VERSION ""

NS_ :

BS_:

BU_: RVCController

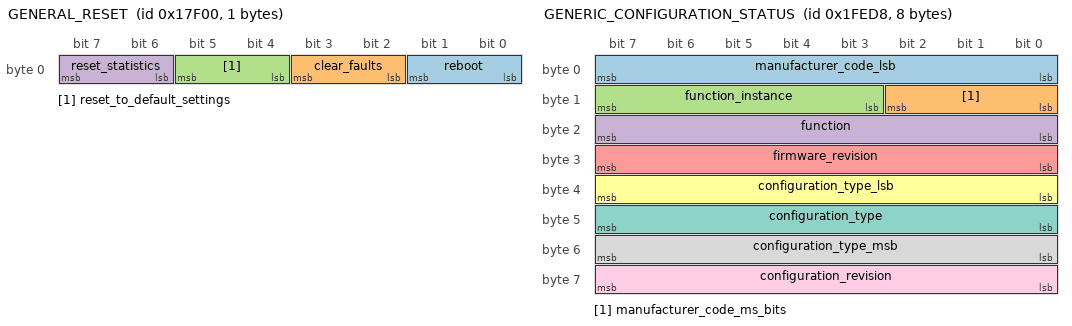
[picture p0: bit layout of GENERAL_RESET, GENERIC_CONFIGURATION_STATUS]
BO_ 98048 GENERAL_RESET: 1 RVCController
 SG_ reboot : 0|2@1+ (1,0) [0|0] "" RVCController
 SG_ clear_faults : 2|2@1+ (1,0) [0|0] "" RVCController
 SG_ reset_to_default_settings : 4|2@1+ (1,0) [0|0] "" RVCController
 SG_ reset_statistics : 6|2@1+ (1,0) [0|0] "" RVCController
VAL_ 98048 reboot 0 "no action" 1 "Reboot" ;
VAL_ 98048 clear_faults 0 "no action" 1 "clear faults" ;
VAL_ 98048 reset_to_default_settings 0 "no action" 1 "reset to default settings" ;
VAL_ 98048 reset_statistics 0 "no action" 1 "reset statistics" ;

BO_ 97792 TERMINAL: 8 RVCController
 SG_ unknown : 0|8@1+ (1,0) [0|0] "" RVCController
 // NOTE: YAML defines this as 8 bytes ASCII. DBC representation is ambiguous. Leaving as is.

BO_ 130776 GENERIC_CONFIGURATION_STATUS: 8 RVCController
 SG_ manufacturer_code_lsb : 0|8@1+ (1,0) [0|0] "" RVCController
 SG_ manufacturer_code_ms_bits : 8|3@1+ (1,0) [0|0] "" RVCController
 SG_ function_instance : 11|5@1+ (1,0) [0|0] "" RVCController
 SG_ function : 16|8@1+ (1,0) [0|0] "" RVCController
 SG_ firmware_revision : 24|8@1+ (1,0) [0|0] "" RVCController
 SG_ configuration_type_lsb : 32|8@1+ (1,0) [0|0] "" RVCController
 SG_ configuration_type : 40|8@1+ (1,0) [0|0] "" RVCController
 SG_ configuration_type_msb : 48|8@1+ (1,0) [0|0] "" RVCController
 SG_ configuration_revision : 56|8@1+ (1,0) [0|0] "" RVCController

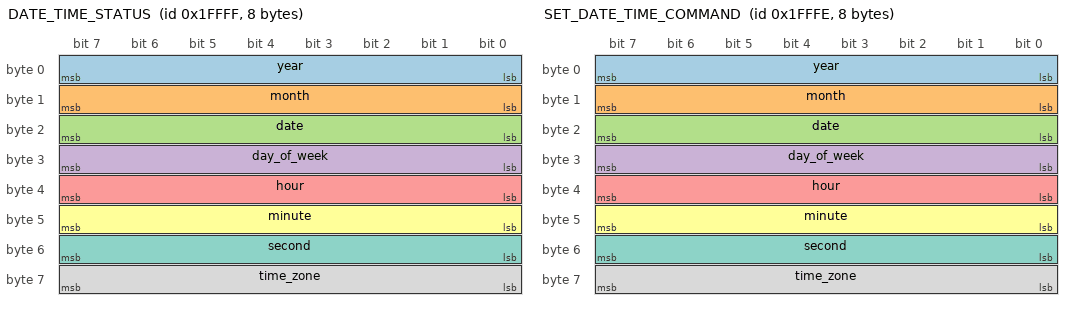
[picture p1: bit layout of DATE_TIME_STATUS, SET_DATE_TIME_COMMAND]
BO_ 131071 DATE_TIME_STATUS: 8 RVCController
 SG_ year : 0|8@1+ (1,0) [0|0] "year" RVCController
 SG_ month : 8|8@1+ (1,0) [0|0] "" RVCController
 SG_ date : 16|8@1+ (1,0) [0|0] "" RVCController
 SG_ day_of_week : 24|8@1+ (1,0) [0|0] "" RVCController
 SG_ hour : 32|8@1+ (1,0) [0|0] "" RVCController
 SG_ minute : 40|8@1+ (1,0) [0|0] "" RVCController
 SG_ second : 48|8@1+ (1,0) [0|0] "" RVCController
 SG_ time_zone : 56|8@1+ (1,0) [0|0] "" RVCController
VAL_ 131071 day_of_week 1 "Sunday" 2 "Monday" 3 "Tuesday" 4 "Wednesday" 5 "Thursday" 6 "Friday" 7 "Saturday" ;
VAL_ 131071 time_zone 0 "Greenwich Mean Time" 4 "Eastern Daylight Time" 5 "Eastern Standard Time" 7 "Pacific Daylight Time" 8 "Pacific Standard Time" 22 "Central European Summer Time" ;

// Add missing alias from YAML: 1FFFE SET_DATE_TIME_COMMAND (alias of 1FFFF)
BO_ 131070 SET_DATE_TIME_COMMAND: 8 RVCController
 SG_ year : 0|8@1+ (1,0) [0|0] "year" RVCController
 SG_ month : 8|8@1+ (1,0) [0|0] "" RVCController
 SG_ date : 16|8@1+ (1,0) [0|0] "" RVCController
 SG_ day_of_week : 24|8@1+ (1,0) [0|0] "" RVCController
 SG_ hour : 32|8@1+ (1,0) [0|0] "" RVCController
 SG_ minute : 40|8@1+ (1,0) [0|0] "" RVCController
 SG_ second : 48|8@1+ (1,0) [0|0] "" RVCController
 SG_ time_zone : 56|8@1+ (1,0) [0|0] "" RVCController
VAL_ 131070 day_of_week 1 "Sunday" 2 "Monday" 3 "Tuesday" 4 "Wednesday" 5 "Thursday" 6 "Friday" 7 "Saturday" ;
VAL_ 131070 time_zone 0 "Greenwich Mean Time" 4 "Eastern Daylight Time" 5 "Eastern Standard Time" 7 "Pacific Daylight Time" 8 "Pacific Standard Time" 22 "Central European Summer Time" ;

BO_ 131069 DC_SOURCE_STATUS_1: 8 RVCController
 SG_ instance : 0|8@1+ (1,0) [0|0] "" RVCController
 SG_ device_priority : 8|8@1+ (1,0) [0|0] "" RVCController
 SG_ dc_voltage : 16|16@1+ (0.001,0) [0|0] "V" RVCController // Assuming scaling based on typical usage
 SG_ dc_current : 32|32@1+ (0.001,0) [0|0] "A" RVCController // Assuming scaling based on typical usage
VAL_ 131069 instance 0 "invalid" 1 "main house battery bank" 2 "chassis start battery" 3 "secondary house battery bank" ;
VAL_ 131069 device_priority 120 "battery soc device" 100 "inverter charger" 80 "charger" 60 "inverter" 40 "voltmeter ammeter" 20 "voltmeter" ; // Corrected 100

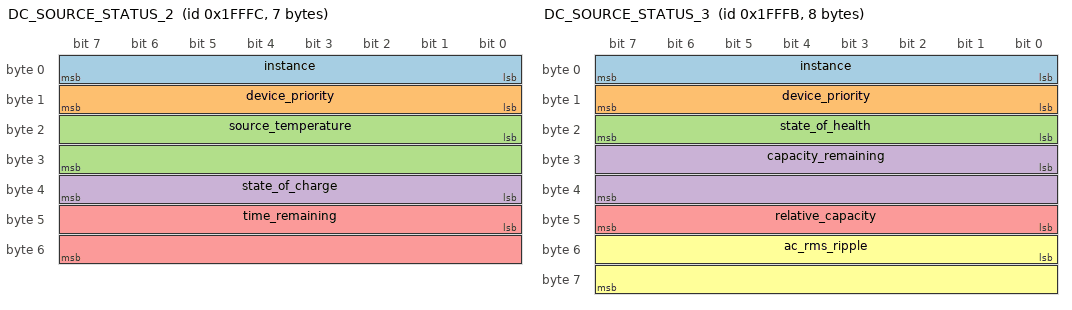
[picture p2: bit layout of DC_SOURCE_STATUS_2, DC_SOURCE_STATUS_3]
BO_ 131068 DC_SOURCE_STATUS_2: 7 RVCController
 SG_ instance : 0|8@1+ (1,0) [0|0] "" RVCController
 SG_ device_priority : 8|8@1+ (1,0) [0|0] "" RVCController
 SG_ source_temperature : 16|16@1+ (0.1,-40) [0|0] "Deg C" RVCController // Assuming scaling based on typical usage
 SG_ state_of_charge : 32|8@1+ (0.5,0) [0|0] "pct" RVCController // Assuming scaling based on typical usage
 SG_ time_remaining : 40|16@1+ (1,0) [0|0] "min" RVCController
VAL_ 131068 instance 0 "invalid" 1 "main house battery bank" 2 "chassis start battery" 3 "secondary house battery bank" ;
VAL_ 131068 device_priority 120 "battery soc device" 100 "inverter Charger" 80 "charger" 60 "inverter" 40 "voltmeter ammeter" 20 "voltmeter" ; // Corrected 100

BO_ 131067 DC_SOURCE_STATUS_3: 8 RVCController
 SG_ instance : 0|8@1+ (1,0) [0|0] "" RVCController
 SG_ device_priority : 8|8@1+ (1,0) [0|0] "" RVCController
 SG_ state_of_health : 16|8@1+ (0.5,0) [0|0] "pct" RVCController // Assuming scaling
 SG_ capacity_remaining : 24|16@1+ (0.1,0) [0|0] "Ah" RVCController // Assuming scaling
 SG_ relative_capacity : 40|8@1+ (0.5,0) [0|0] "pct" RVCController // Assuming scaling
 SG_ ac_rms_ripple : 48|16@1+ (1,0) [0|0] "mV" RVCController
VAL_ 131067 instance 0 "invalid" 1 "main house battery bank" 2 "chassis start battery" 3 "secondary house battery bank" ;
VAL_ 131067 device_priority 120 "battery soc device" 100 "inverter charger" 80 "charger" 60 "inverter" 40 "voltmeter ammeter" 20 "voltmeter" ; // Corrected 100

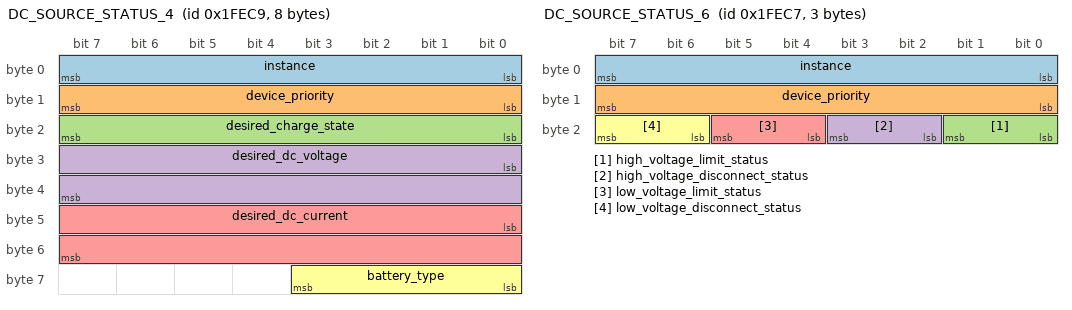
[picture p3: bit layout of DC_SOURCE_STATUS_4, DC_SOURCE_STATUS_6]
BO_ 130761 DC_SOURCE_STATUS_4: 8 RVCController
 SG_ instance : 0|8@1+ (1,0) [0|0] "" RVCController
 SG_ device_priority : 8|8@1+ (1,0) [0|0] "" RVCController
 SG_ desired_charge_state : 16|8@1+ (1,0) [0|0] "" RVCController
 SG_ desired_dc_voltage : 24|16@1+ (0.001,0) [0|0] "V" RVCController // Assuming scaling
 SG_ desired_dc_current : 40|16@1+ (0.1,0) [0|0] "A" RVCController // Assuming scaling
 SG_ battery_type : 56|4@1+ (1,0) [0|0] "" RVCController
VAL_ 130761 instance 0 "invalid" 1 "main house battery bank" 2 "chassis start battery" 3 "secondary house battery bank" ;
VAL_ 130761 device_priority 120 "battery soc device" 100 "inverter charger" 80 "charger" 60 "inverter" 40 "voltmeter ammeter" 20 "voltmeter" ; // Corrected 100
VAL_ 130761 desired_charge_state 0 "undefined" 1 "do not charge" 2 "bulk" 3 "absorbtion" 4 "overcharge" 5 "equalize" 6 "float" 7 "constant voltage current" ;
VAL_ 130761 battery_type 0 "flooded" 1 "gel" 2 "agm" 3 "lithium iron phosphate" ;

BO_ 130760 DC_SOURCE_STATUS_5: 8 RVCController
 SG_ instance : 0|8@1+ (1,0) [0|0] "" RVCController
 SG_ device_priority : 8|8@1+ (1,0) [0|0] "" RVCController
 SG_ hp_dc_voltage : 16|32@1+ (0.000001,0) [0|0] "V" RVCController // Assuming scaling
 SG_ dc_voltage_rate_of_change : 48|16@1+ (0.001,0) [0|0] "mV/s" RVCController // Assuming scaling
VAL_ 130760 instance 0 "invalid" 1 "main house battery bank" 2 "chassis start battery" 3 "secondary house battery bank" ;
VAL_ 130760 device_priority 120 "battery soc device" 100 "inverter charger" 80 "charger" 60 "inverter" 40 "voltmeter ammeter" 20 "voltmeter" ; // Corrected 100

BO_ 130759 DC_SOURCE_STATUS_6: 3 RVCController
 SG_ instance : 0|8@1+ (1,0) [0|0] "" RVCController
 SG_ device_priority : 8|8@1+ (1,0) [0|0] "" RVCController
 SG_ high_voltage_limit_status : 16|2@1+ (1,0) [0|0] "" RVCController
 SG_ high_voltage_disconnect_status : 18|2@1+ (1,0) [0|0] "" RVCController
 SG_ low_voltage_limit_status : 20|2@1+ (1,0) [0|0] "" RVCController
 SG_ low_voltage_disconnect_status : 22|2@1+ (1,0) [0|0] "" RVCController
VAL_ 130759 instance 0 "invalid" 1 "main house battery bank" 2 "chassis start battery" 3 "secondary house battery bank" ;
VAL_ 130759 device_priority 120 "battery soc device" 100 "inverter charger" 80 "charger" 60 "inverter" 40 "voltmeter ammeter" 20 "voltmeter" ; // Corrected 100
VAL_ 130759 high_voltage_limit_status 0 "not reached" 1 "limit reached" ;
VAL_ 130759 high_voltage_disconnect_status 0 "connected" 1 "charge bus disconnected" ;
VAL_ 130759 low_voltage_limit_status 0 "not reached" 1 "limit reached" ;
VAL_ 130759 low_voltage_disconnect_status 0 "connected" 1 "charge bus disconnected" ;

// Add missing alias from YAML: 10FFD DC_SOURCE_STATUS_SPYDER (alias of 1FFFD)
BO_ 69629 DC_SOURCE_STATUS_SPYDER: 8 RVCController
 SG_ instance : 0|8@1+ (1,0) [0|0] "" RVCController
 SG_ device_priority : 8|8@1+ (1,0) [0|0] "" RVCController
 SG_ dc_voltage : 16|16@1+ (0.001,0) [0|0] "V" RVCController // Assuming scaling
 SG_ dc_current : 32|32@1+ (0.001,0) [0|0] "A" RVCController // Assuming scaling
VAL_ 69629 instance 0 "invalid" 1 "main house battery bank" 2 "chassis start battery" 3 "secondary house battery bank" ;
VAL_ 69629 device_priority 120 "battery soc device" 100 "inverter charger" 80 "charger" 60 "inverter" 40 "voltmeter ammeter" 20 "voltmeter" ; // Corrected 100

BO_ 131066 COMMUNICATION_STATUS_1: 8 RVCController
 SG_ timer_count : 0|32@1+ (1,0) [0|0] "ms" RVCController
 SG_ receive_error_count : 32|16@1+ (1,0) [0|0] "" RVCController
 SG_ transmit_error_count : 48|16@1+ (1,0) [0|0] "" RVCController

BO_ 131065 COMMUNICATION_STATUS_2: 8 RVCController
 SG_ transmitted_frames_count : 0|32@1+ (1,0) [0|0] "" RVCController
 SG_ received_frames_count : 32|32@1+ (1,0) [0|0] "" RVCController

BO_ 131064 COMMUNICATION_STATUS_3: 6 RVCController
 SG_ bus_off_error_count : 0|16@1+ (1,0) [0|0] "" RVCController
 SG_ receive_frames_dropped_count : 16|16@1+ (1,0) [0|0] "" RVCController
 SG_ transmit_frames_dropped_count : 32|16@1+ (1,0) [0|0] "" RVCController

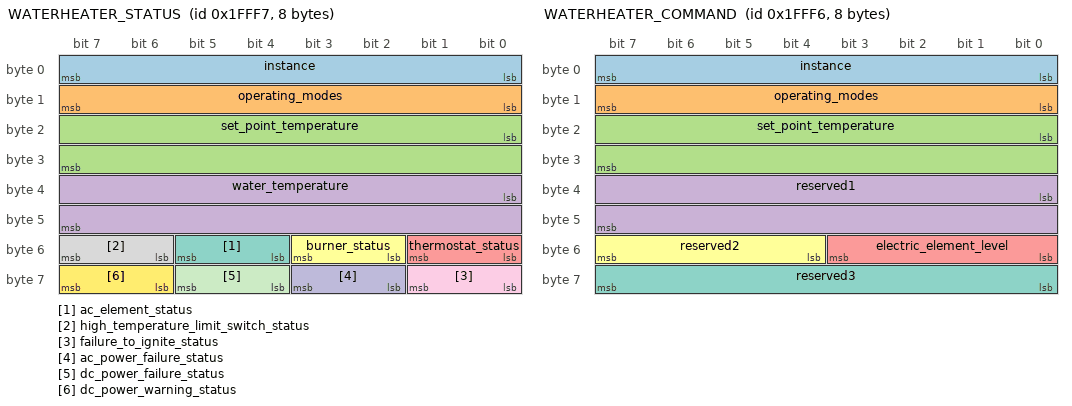
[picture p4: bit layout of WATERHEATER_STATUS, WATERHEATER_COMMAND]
BO_ 131063 WATERHEATER_STATUS: 8 RVCController
 SG_ instance : 0|8@1+ (1,0) [0|0] "" RVCController
 SG_ operating_modes : 8|8@1+ (1,0) [0|0] "" RVCController
 SG_ set_point_temperature : 16|16@1+ (0.1,0) [0|0] "Deg C" RVCController // Assuming scaling
 SG_ water_temperature : 32|16@1+ (0.1,0) [0|0] "Deg C" RVCController // Assuming scaling
 SG_ thermostat_status : 48|2@1+ (1,0) [0|0] "" RVCController
 SG_ burner_status : 50|2@1+ (1,0) [0|0] "" RVCController
 SG_ ac_element_status : 52|2@1+ (1,0) [0|0] "" RVCController
 SG_ high_temperature_limit_switch_status : 54|2@1+ (1,0) [0|0] "" RVCController
 SG_ failure_to_ignite_status : 56|2@1+ (1,0) [0|0] "" RVCController
 SG_ ac_power_failure_status : 58|2@1+ (1,0) [0|0] "" RVCController
 SG_ dc_power_failure_status : 60|2@1+ (1,0) [0|0] "" RVCController
 SG_ dc_power_warning_status : 62|2@1+ (1,0) [0|0] "" RVCController
VAL_ 131063 operating_modes 0 "off" 1 "combustion" 2 "electric" 3 "gas/electric (both)" 4 "automatic (electric if available, otherwise combustion)" 5 "test combustion (forced on)" 6 "test electric (forced on)" ; // Corrected 0 value
VAL_ 131063 thermostat_status 0 "set point met" 1 "set point not met (heat is being applied)" ;
VAL_ 131063 burner_status 0 "off" 1 "burner is lit" ; // Corrected 0 value
VAL_ 131063 ac_element_status 0 "ac element is inactive" 1 "ac element is active" ;
VAL_ 131063 high_temperature_limit_switch_status 0 "limit switch not tripped" 1 "limit switch tripped" ;
VAL_ 131063 failure_to_ignite_status 0 "no failure" 1 "device has failed to ignite" ;
VAL_ 131063 ac_power_failure_status 0 "ac power present" 1 "ac power not present" ;
VAL_ 131063 dc_power_failure_status 0 "dc power present" 1 "dc power not present" ;
VAL_ 131063 dc_power_warning_status 0 "dc power sufficient" 1 "dc power warning" ;

BO_ 131062 WATERHEATER_COMMAND: 8 RVCController
 SG_ instance : 0|8@1+ (1,0) [0|0] "" RVCController
 SG_ operating_modes : 8|8@1+ (1,0) [0|0] "" RVCController
 SG_ set_point_temperature : 16|16@1+ (0.1,0) [0|0] "" RVCController // Assuming scaling
 SG_ reserved1 : 32|16@1+ (1,0) [0|0] "" RVCController // Renamed reserved
 SG_ electric_element_level : 48|4@1+ (1,0) [0|0] "" RVCController
 SG_ reserved2 : 52|4@1+ (1,0) [0|0] "" RVCController // Renamed reserved
 SG_ reserved3 : 56|8@1+ (1,0) [0|0] "" RVCController // Renamed reserved
VAL_ 131062 operating_modes 0 "off" 1 "combustion" 2 "electric" 3 "gas/electric (both)" 4 "automatic (electric if available, combustion otherwise)" 5 "test combustion (forced on)" 6 "test electric (forced on)" ; // Corrected 0 value

BO_ 130713 WATERHEATER_STATUS_2: 8 RVCController
 SG_ instance : 0|8@1+ (1,0) [0|0] "" RVCController
 SG_ electric_element_level : 8|4@1+ (1,0) [0|0] "" RVCController
 SG_ max_electric_element_level : 12|4@1+ (1,0) [0|0] "" RVCController
 SG_ engine_preheat : 16|4@1+ (1,0) [0|0] "" RVCController
 SG_ coolant_level_warning : 20|2@1+ (1,0) [0|0] "" RVCController
 SG_ hot_water_priority : 22|2@1+ (1,0) [0|0] "" RVCController
 SG_ output_status_burner : 24|2@1+ (1,0) [0|0] "" RVCController // Normalized name
 SG_ output_status_burner_indicator : 26|2@1+ (1,0) [0|0] "" RVCController // Normalized name
 SG_ output_status_electric_low : 28|2@1+ (1,0) [0|0] "" RVCController // Normalized name
 SG_ output_status_electric_high : 30|2@1+ (1,0) [0|0] "" RVCController // Normalized name
 SG_ burner_overcurrent_status : 32|2@1+ (1,0) [0|0] "" RVCController
 SG_ burner_undercurrent_status : 34|2@1+ (1,0) [0|0] "" RVCController
 SG_ burner_temperature_status : 36|2@1+ (1,0) [0|0] "" RVCController
 SG_ burner_input_status : 38|2@1+ (1,0) [0|0] "" RVCController
 SG_ burner_indicator_overcurrent_status : 40|2@1+ (1,0) [0|0] "" RVCController
 SG_ burner_indicator_undercurrent_status : 42|2@1+ (1,0) [0|0] "" RVCController
 SG_ burner_indicator_temperature_status : 44|2@1+ (1,0) [0|0] "" RVCController
 SG_ reserved : 46|2@1+ (1,0) [0|0] "" RVCController
 SG_ electric_low_overcurrent_status : 48|2@1+ (1,0) [0|0] "" RVCController
 SG_ electric_low_undercurrent_status : 50|2@1+ (1,0) [0|0] "" RVCController
 SG_ electric_low_temperature_status : 52|2@1+ (1,0) [0|0] "" RVCController
 SG_ electric_low_input_status : 54|2@1+ (1,0) [0|0] "" RVCController
 SG_ electric_high_element_overcurrent_status : 56|2@1+ (1,0) [0|0] "" RVCController
 SG_ electric_high_element_undercurrent_status : 58|2@1+ (1,0) [0|0] "" RVCController
 SG_ electric_high_element_temperature_status : 60|2@1+ (1,0) [0|0] "" RVCController
 SG_ electric_high_element_input_status : 62|2@1+ (1,0) [0|0] "" RVCController
VAL_ 130713 engine_preheat 0 "off" 1 "on" 5 "test (forced on)" ; // Corrected values
VAL_ 130713 coolant_level_warning 0 "coolant level sufficent" 1 "coolant level low (shutoff)" ;
VAL_ 130713 hot_water_priority 0 "domestic water priority" 1 "heating priority" ;
VAL_ 130713 output_status_burner 0 "off" 1 "on" ; // Normalized name and values
VAL_ 130713 output_status_burner_indicator 0 "off" 1 "on" ; // Normalized name and values
VAL_ 130713 output_status_electric_low 0 "off" 1 "on" ; // Normalized name and values
VAL_ 130713 output_status_electric_high 0 "off" 1 "on" ; // Normalized name and values
VAL_ 130713 burner_overcurrent_status 0 "no overcurrent detected" 1 "overcurrent detected" ;
VAL_ 130713 burner_undercurrent_status 0 "no undercurrent detected" 1 "undercurrent detected" ;
VAL_ 130713 burner_temperature_status 0 "temperature normal" 1 "temperature warning" ;
VAL_ 130713 burner_input_status 0 "off (inactive)" 1 "on (active)" ;
VAL_ 130713 burner_indicator_overcurrent_status 0 "no overcurrent detected" 1 "overcurrent detected" ;
VAL_ 130713 burner_indicator_undercurrent_status 0 "no undercurrent detected" 1 "undercurrent detected" ;
VAL_ 130713 burner_indicator_temperature_status 0 "temperature normal" 1 "temperature warning" ;
VAL_ 130713 electric_low_overcurrent_status 0 "no overcurrent detected" 1 "overcurrent detected" ;
VAL_ 130713 electric_low_undercurrent_status 0 "no undercurrent detected" 1 "undercurrent detected" ;
VAL_ 130713 electric_low_temperature_status 0 "temperature normal" 1 "temperature warning" ;
VAL_ 130713 electric_low_input_status 0 "off (inactive)" 1 "on (active)" ;
VAL_ 130713 electric_high_element_overcurrent_status 0 "no overcurrent detected" 1 "overcurrent detected" ;
VAL_ 130713 electric_high_element_undercurrent_status 0 "no undercurrent detected" 1 "undercurrent detected" ;
VAL_ 130713 electric_high_element_temperature_status 0 "temperature normal" 1 "temperature warning" ;
VAL_ 130713 electric_high_element_input_status 0 "off (inactive)" 1 "on (active)" ;

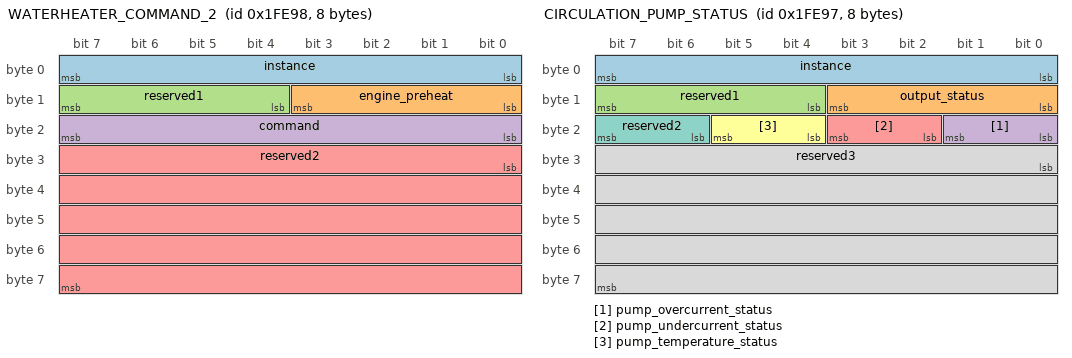
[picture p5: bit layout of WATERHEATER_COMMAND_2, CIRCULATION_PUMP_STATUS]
BO_ 130712 WATERHEATER_COMMAND_2: 8 RVCController
 SG_ instance : 0|8@1+ (1,0) [0|0] "" RVCController
 SG_ engine_preheat : 8|4@1+ (1,0) [0|0] "" RVCController
 SG_ reserved1 : 12|4@1+ (1,0) [0|0] "" RVCController // Renamed reserved
 SG_ command : 16|8@1+ (1,0) [0|0] "" RVCController
 SG_ reserved2 : 24|40@1+ (1,0) [0|0] "" RVCController // Renamed reserved, corrected length
VAL_ 130712 engine_preheat 0 "off" 1 "on" 5 "test (forced on)" ; // Corrected values
VAL_ 130712 command 0 "electric low - enable" 1 "electric low - disable" 2 "electric low - toggle" 3 "electric high - enable" 4 "electric High - disable" 5 "electric High - toggle" 6 "burner - enable" 7 "burner - disable" 8 "burner - toggle" 9 "electric - cycle (low to high to off)" 10 "electric - cycle (high to low to off)" 11 "electric low test - toggle" 12 "electric high test - toggle" 13 "burner test - toggle" ; // Corrected values 10-13

// Add missing message from YAML: 1FE97 CIRCULATION_PUMP_STATUS
BO_ 130711 CIRCULATION_PUMP_STATUS: 8 RVCController // Assuming length 8 based on reserved bits
 SG_ instance : 0|8@1+ (1,0) [0|0] "" RVCController
 SG_ output_status : 8|4@1+ (1,0) [0|0] "" RVCController
 SG_ reserved1 : 12|4@1+ (1,0) [0|0] "" RVCController
 SG_ pump_overcurrent_status : 16|2@1+ (1,0) [0|0] "" RVCController
 SG_ pump_undercurrent_status : 18|2@1+ (1,0) [0|0] "" RVCController // Corrected length based on values
 SG_ pump_temperature_status : 20|2@1+ (1,0) [0|0] "" RVCController // Corrected length based on values
 SG_ reserved2 : 22|2@1+ (1,0) [0|0] "" RVCController
 SG_ reserved3 : 24|40@1+ (1,0) [0|0] "" RVCController
VAL_ 130711 output_status 0 "off" 1 "on" 5 "test (forced on)" ;
VAL_ 130711 pump_overcurrent_status 0 "no overcurrent detected" 1 "overcurrent detected" ;
VAL_ 130711 pump_undercurrent_status 0 "no undercurrent detected" 1 "undercurrent detected" ;
VAL_ 130711 pump_temperature_status 0 "temperature normal" 1 "temperature warning" ;

// Add missing message from YAML: 1FE96 CIRCULATION_PUMP_COMMAND
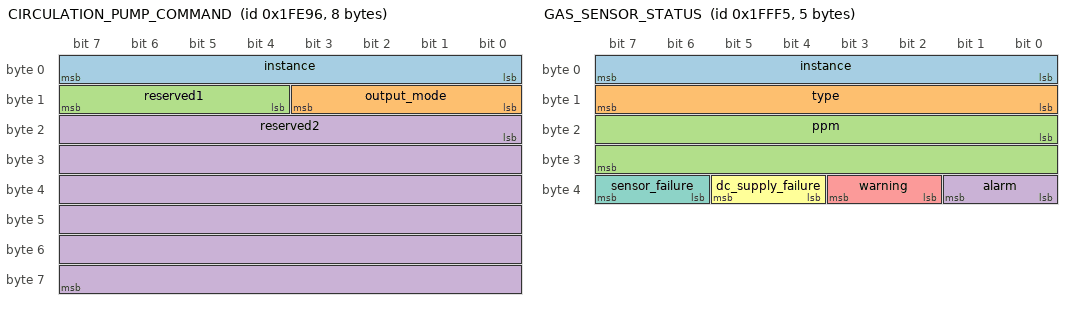
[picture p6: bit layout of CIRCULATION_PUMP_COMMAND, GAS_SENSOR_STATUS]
BO_ 130710 CIRCULATION_PUMP_COMMAND: 8 RVCController // Assuming length 8 based on reserved bits
 SG_ instance : 0|8@1+ (1,0) [0|0] "" RVCController
 SG_ output_mode : 8|4@1+ (1,0) [0|0] "" RVCController
 SG_ reserved1 : 12|4@1+ (1,0) [0|0] "" RVCController
 SG_ reserved2 : 16|48@1+ (1,0) [0|0] "" RVCController
VAL_ 130710 output_mode 0 "off" 5 "test (forced on)" ;

BO_ 131061 GAS_SENSOR_STATUS: 5 RVCController
 SG_ instance : 0|8@1+ (1,0) [0|0] "" RVCController
 SG_ type : 8|8@1+ (1,0) [0|0] "" RVCController
 SG_ ppm : 16|16@1+ (1,0) [0|0] "ppm" RVCController
 SG_ alarm : 32|2@1+ (1,0) [0|0] "" RVCController // Removed unit="bit"
 SG_ warning : 34|2@1+ (1,0) [0|0] "" RVCController // Removed unit="bit"
 SG_ dc_supply_failure : 36|2@1+ (1,0) [0|0] "" RVCController // Removed unit="bit"
 SG_ sensor_failure : 38|2@1+ (1,0) [0|0] "" RVCController // Removed unit="bit"
VAL_ 131061 type 1 "co" 2 "lp gas" 3 "smoke" ;
VAL_ 131061 alarm 0 "no alarm" 1 "alarm" ;
VAL_ 131061 warning 0 "no warning" 1 "warning" ;
VAL_ 131061 dc_supply_failure 0 "no failure" 1 "failure" ;
VAL_ 131061 sensor_failure 0 "no failure" 1 "failure" ;

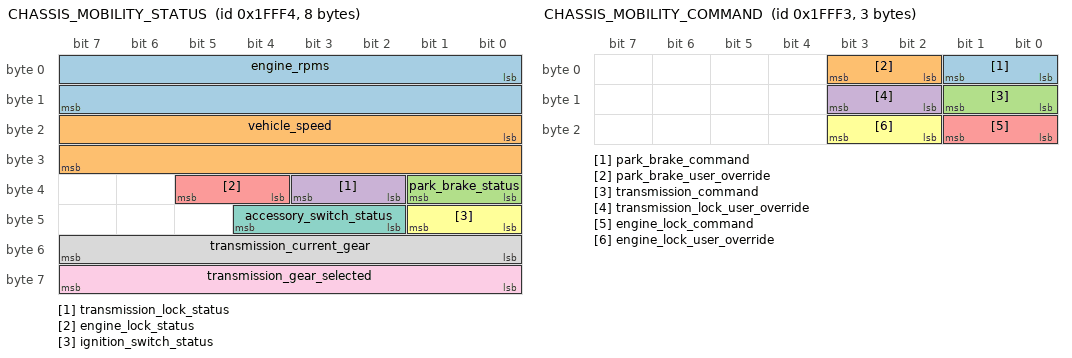
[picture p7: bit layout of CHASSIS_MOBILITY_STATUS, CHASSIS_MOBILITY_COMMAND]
BO_ 131060 CHASSIS_MOBILITY_STATUS: 8 RVCController
 SG_ engine_rpms : 0|16@1+ (1,0) [0|0] "rpm" RVCController
 SG_ vehicle_speed : 16|16@1+ (0.01,0) [0|0] "kph" RVCController // Assuming scaling
 SG_ park_brake_status : 32|2@1+ (1,0) [0|0] "" RVCController
 SG_ transmission_lock_status : 34|2@1+ (1,0) [0|0] "" RVCController
 SG_ engine_lock_status : 36|2@1+ (1,0) [0|0] "" RVCController
 SG_ ignition_switch_status : 40|2@1+ (1,0) [0|0] "" RVCController
 SG_ accessory_switch_status : 42|3@1+ (1,0) [0|0] "" RVCController // Length 3 bits
 SG_ transmission_current_gear : 48|8@1+ (1,0) [0|0] "" RVCController
 SG_ transmission_gear_selected : 56|8@1+ (1,0) [0|0] "" RVCController
VAL_ 131060 park_brake_status 0 "park brake released" 1 "park brake engaged" ;
VAL_ 131060 transmission_lock_status 0 "transmission not locked" 1 "transmission locked" ;
VAL_ 131060 engine_lock_status 0 "engine free to start" 1 "engine locked" ;
VAL_ 131060 ignition_switch_status 0 "off" 1 "on" ; // Corrected values
VAL_ 131060 accessory_switch_status 0 "off" 1 "on" ; // Corrected values
VAL_ 131060 transmission_current_gear 124 "reverse 1" 125 "neutral" 126 "forward 1" 127 "forward 2" 128 "forward 3" 129 "forward 4" 130 "forward 5" 131 "forward 6" 132 "forward 7" 251 "park" ;
VAL_ 131060 transmission_gear_selected 124 "reverse 1" 125 "neutral" 126 "forward 1" 127 "forward 2" 128 "forward 3" 129 "forward 4" 130 "forward 5" 131 "forward 6" 132 "forward 7" 251 "park" ;

BO_ 131059 CHASSIS_MOBILITY_COMMAND: 3 RVCController
 SG_ park_brake_command : 0|2@1+ (1,0) [0|0] "" RVCController
 SG_ park_brake_user_override : 2|2@1+ (1,0) [0|0] "" RVCController
 SG_ transmission_command : 8|2@1+ (1,0) [0|0] "" RVCController
 SG_ transmission_lock_user_override : 10|2@1+ (1,0) [0|0] "" RVCController
 SG_ engine_lock_command : 16|2@1+ (1,0) [0|0] "" RVCController
 SG_ engine_lock_user_override : 18|2@1+ (1,0) [0|0] "" RVCController
VAL_ 131059 park_brake_command 0 "please release chassis" 1 "please immobilize chassis" 2 "error" 3 "do not care about status" ;
VAL_ 131059 park_brake_user_override 0 "normal priority" 1 "override" 2 "error" 3 "na" ;
VAL_ 131059 transmission_command 0 "please release transmission" 1 "please lock transmission" 2 "error" 3 "do not care about status" ;
VAL_ 131059 transmission_lock_user_override 0 "normal priority" 1 "override" 2 "error" 3 "na" ;
VAL_ 131059 engine_lock_command 0 "please release engine" 1 "please lock engine" 2 "error" 3 "do not care about status" ;
VAL_ 131059 engine_lock_user_override 0 "normal priority" 1 "override" 2 "error" 3 "na" ;

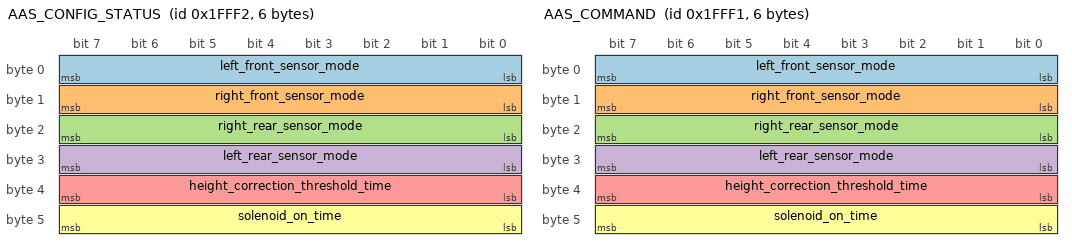
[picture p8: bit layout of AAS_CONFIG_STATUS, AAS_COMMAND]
BO_ 131058 AAS_CONFIG_STATUS: 6 RVCController
 SG_ left_front_sensor_mode : 0|8@1+ (1,0) [0|0] "Pct" RVCController
 SG_ right_front_sensor_mode : 8|8@1+ (1,0) [0|0] "Pct" RVCController
 SG_ right_rear_sensor_mode : 16|8@1+ (1,0) [0|0] "Pct" RVCController
 SG_ left_rear_sensor_mode : 24|8@1+ (1,0) [0|0] "Pct" RVCController
 SG_ height_correction_threshold_time : 32|8@1+ (1,0) [0|0] "min" RVCController
 SG_ solenoid_on_time : 40|8@1+ (1,0) [0|0] "min" RVCController

// Add missing alias from YAML: 1FFF1 AAS_COMMAND (alias of 1FFF2)
BO_ 131057 AAS_COMMAND: 6 RVCController
 SG_ left_front_sensor_mode : 0|8@1+ (1,0) [0|0] "Pct" RVCController
 SG_ right_front_sensor_mode : 8|8@1+ (1,0) [0|0] "Pct" RVCController
 SG_ right_rear_sensor_mode : 16|8@1+ (1,0) [0|0] "Pct" RVCController
 SG_ left_rear_sensor_mode : 24|8@1+ (1,0) [0|0] "Pct" RVCController
 SG_ height_correction_threshold_time : 32|8@1+ (1,0) [0|0] "min" RVCController
 SG_ solenoid_on_time : 40|8@1+ (1,0) [0|0] "min" RVCController

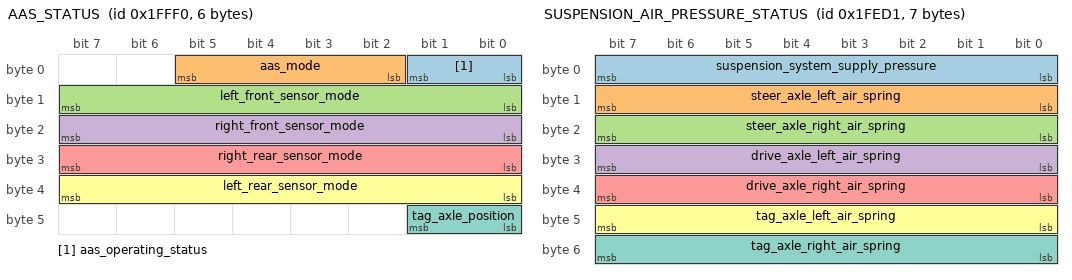
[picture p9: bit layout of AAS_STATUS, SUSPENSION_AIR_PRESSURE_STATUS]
BO_ 131056 AAS_STATUS: 6 RVCController
 SG_ aas_operating_status : 0|2@1+ (1,0) [0|0] "" RVCController
 SG_ aas_mode : 2|4@1+ (1,0) [0|0] "" RVCController
 SG_ left_front_sensor_mode : 8|8@1+ (1,0) [0|0] "Pct" RVCController
 SG_ right_front_sensor_mode : 16|8@1+ (1,0) [0|0] "Pct" RVCController
 SG_ right_rear_sensor_mode : 24|8@1+ (1,0) [0|0] "Pct" RVCController
 SG_ left_rear_sensor_mode : 32|8@1+ (1,0) [0|0] "Pct" RVCController
 SG_ tag_axle_position : 40|2@1+ (1,0) [0|0] "" RVCController
VAL_ 131056 aas_operating_status 0 "off" 1 "on" ; // Corrected values
VAL_ 131056 aas_mode 0 "normal" 1 "fly mode" 2 "reset" 14 "error" 15 "na" ; // Corrected value 2 (was 8)
VAL_ 131056 tag_axle_position 0 "down" 1 "up" ;

BO_ 131055 AAS_SENSOR_STATUS: 8 RVCController
 SG_ left_front_sensor_status_low_ride : 0|2@1+ (1,0) [0|0] "" RVCController
 SG_ left_front_sensor_status_medium_ride : 2|2@1+ (1,0) [0|0] "" RVCController
 SG_ left_front_sensor_status_high_ride : 4|2@1+ (1,0) [0|0] "" RVCController
 SG_ left_front_sensor_transition : 6|2@1+ (1,0) [0|0] "" RVCController
 SG_ left_front_quadrature_encoder_status_channel_a : 8|2@1+ (1,0) [0|0] "" RVCController
 SG_ left_front_quadrature_encoder_status_channel_b : 10|2@1+ (1,0) [0|0] "" RVCController
 SG_ right_front_sensor_status_low_ride : 16|2@1+ (1,0) [0|0] "" RVCController
 SG_ right_front_sensor_status_medium_ride : 18|2@1+ (1,0) [0|0] "" RVCController
 SG_ right_front_sensor_status_high_ride : 20|2@1+ (1,0) [0|0] "" RVCController
 SG_ right_front_sensor_transition : 22|2@1+ (1,0) [0|0] "" RVCController
 SG_ right_front_quadrature_encoder_status_channel_a : 24|2@1+ (1,0) [0|0] "" RVCController
 SG_ right_front_quadrature_encoder_status_channel_b : 26|2@1+ (1,0) [0|0] "" RVCController
 SG_ steering_sensor_quadrature_encoder_status_channel_a : 28|2@1+ (1,0) [0|0] "" RVCController
 SG_ steering_sensor_quadrature_encoder_status_channel_b : 30|2@1+ (1,0) [0|0] "" RVCController
 SG_ left_rear_sensor_status_low_ride : 32|2@1+ (1,0) [0|0] "" RVCController
 SG_ left_rear_sensor_status_medium_ride : 34|2@1+ (1,0) [0|0] "" RVCController
 SG_ left_rear_sensor_status_high_ride : 36|2@1+ (1,0) [0|0] "" RVCController
 SG_ left_rear_sensor_transition : 38|2@1+ (1,0) [0|0] "" RVCController
 SG_ left_rear_quadrature_encoder_status_channel_a : 40|2@1+ (1,0) [0|0] "" RVCController
 SG_ left_rear_quadrature_encoder_status_channel_b : 42|2@1+ (1,0) [0|0] "" RVCController
 SG_ right_rear_sensor_status_low_ride : 48|2@1+ (1,0) [0|0] "" RVCController
 SG_ right_rear_sensor_status_medium_ride : 50|2@1+ (1,0) [0|0] "" RVCController
 SG_ right_rear_sensor_status_high_ride : 52|2@1+ (1,0) [0|0] "" RVCController
 SG_ right_rear_sensor_transition : 54|2@1+ (1,0) [0|0] "" RVCController
 SG_ right_rear_quadrature_encoder_status_channel_a : 56|2@1+ (1,0) [0|0] "" RVCController
 SG_ right_rear_quadrature_encoder_status_channel_b : 58|2@1+ (1,0) [0|0] "" RVCController
VAL_ 131055 left_front_sensor_status_low_ride 0 "under set point" 1 "over set point" ;
VAL_ 131055 left_front_sensor_status_medium_ride 0 "under set point" 1 "over set point" ;
VAL_ 131055 left_front_sensor_status_high_ride 0 "under set point" 1 "over set point" ;
VAL_ 131055 left_front_sensor_transition 0 "no transition" 1 "transition was made" ;
VAL_ 131055 right_front_sensor_status_low_ride 0 "under set point" 1 "over set point" ;
VAL_ 131055 right_front_sensor_status_medium_ride 0 "under set point" 1 "over set point" ;
VAL_ 131055 right_front_sensor_status_high_ride 0 "under set point" 1 "over set point" ;
VAL_ 131055 right_front_sensor_transition 0 "no transition" 1 "transition was made" ;
VAL_ 131055 left_rear_sensor_status_low_ride 0 "under set point" 1 "over set point" ;
VAL_ 131055 left_rear_sensor_status_medium_ride 0 "under set point" 1 "over set point" ;
VAL_ 131055 left_rear_sensor_status_high_ride 0 "under set point" 1 "over set point" ;
VAL_ 131055 left_rear_sensor_transition 0 "no transition" 1 "transition was made" ;
VAL_ 131055 right_rear_sensor_status_low_ride 0 "under set point" 1 "over set point" ;
VAL_ 131055 right_rear_sensor_status_medium_ride 0 "under set point" 1 "over set point" ;
VAL_ 131055 right_rear_sensor_status_high_ride 0 "under set point" 1 "over set point" ;
VAL_ 131055 right_rear_sensor_transition 0 "no transition" 1 "transition was made" ;

BO_ 130769 SUSPENSION_AIR_PRESSURE_STATUS: 7 RVCController
 SG_ suspension_system_supply_pressure : 0|8@1+ (1,0) [0|0] "" RVCController
 SG_ steer_axle_left_air_spring : 8|8@1+ (1,0) [0|0] "" RVCController
 SG_ steer_axle_right_air_spring : 16|8@1+ (1,0) [0|0] "" RVCController
 SG_ drive_axle_left_air_spring : 24|8@1+ (1,0) [0|0] "" RVCController
 SG_ drive_axle_right_air_spring : 32|8@1+ (1,0) [0|0] "" RVCController
 SG_ tag_axle_left_air_spring : 40|8@1+ (1,0) [0|0] "" RVCController
 SG_ tag_axle_right_air_spring : 48|8@1+ (1,0) [0|0] "" RVCController // Corrected name

// Messages 1FFEE to 1FEBC have empty definitions in YAML, leaving DBC as is.
BO_ 131054 LEVELING_CONTROL_COMMAND: 1 RVCController
// ...existing code...
BO_ 130748 HYDRAULIC_PUMP_COMMAND: 1 RVCController
// ...existing code...
BO_ 131049 LEVELING_AIR_STATUS: 1 RVCController
// ...existing code...
BO_ 131045 SLIDE_MOTOR_STATUS: 1 RVCController
// ...existing code...
BO_ 131044 FURNACE_STATUS: 1 RVCController
// ...existing code...
BO_ 131043 FURNACE_COMMAND: 1 RVCController
// ...existing code...
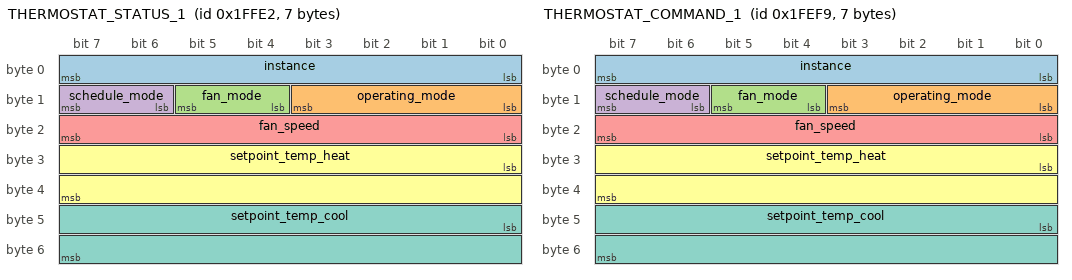
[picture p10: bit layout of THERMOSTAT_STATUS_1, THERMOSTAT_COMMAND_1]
BO_ 131042 THERMOSTAT_STATUS_1: 7 RVCController
 SG_ instance : 0|8@1+ (1,0) [0|0] "" RVCController
 SG_ operating_mode : 8|4@1+ (1,0) [0|0] "" RVCController
 SG_ fan_mode : 12|2@1+ (1,0) [0|0] "" RVCController
 SG_ schedule_mode : 14|2@1+ (1,0) [0|0] "" RVCController
 SG_ fan_speed : 16|8@1+ (0.5,0) [0|0] "Pct" RVCController // Assuming scaling
 SG_ setpoint_temp_heat : 24|16@1+ (0.1,0) [0|0] "Deg C" RVCController // Assuming scaling
 SG_ setpoint_temp_cool : 40|16@1+ (0.1,0) [0|0] "Deg C" RVCController // Assuming scaling
VAL_ 131042 operating_mode 0 "off" 1 "cool" 2 "heat" 3 "auto" 4 "fan only" ; // Corrected values
VAL_ 131042 fan_mode 0 "auto" 1 "on" ; // Corrected values
VAL_ 131042 schedule_mode 0 "disabled" 1 "enabled" ; // Corrected values

BO_ 130810 THERMOSTAT_STATUS_2: 3 RVCController
 SG_ instance : 0|8@1+ (1,0) [0|0] "" RVCController
 SG_ current_schedule_instance : 8|8@1+ (1,0) [0|0] "" RVCController
 SG_ number_of_schedule_instances : 16|8@1+ (1,0) [0|0] "" RVCController

// Add missing alias from YAML: 1FEF9 THERMOSTAT_COMMAND_1 (alias of 1FFE2)
BO_ 130809 THERMOSTAT_COMMAND_1: 7 RVCController
 SG_ instance : 0|8@1+ (1,0) [0|0] "" RVCController
 SG_ operating_mode : 8|4@1+ (1,0) [0|0] "" RVCController
 SG_ fan_mode : 12|2@1+ (1,0) [0|0] "" RVCController
 SG_ schedule_mode : 14|2@1+ (1,0) [0|0] "" RVCController
 SG_ fan_speed : 16|8@1+ (0.5,0) [0|0] "Pct" RVCController // Assuming scaling
 SG_ setpoint_temp_heat : 24|16@1+ (0.1,0) [0|0] "Deg C" RVCController // Assuming scaling
 SG_ setpoint_temp_cool : 40|16@1+ (0.1,0) [0|0] "Deg C" RVCController // Assuming scaling
VAL_ 130809 operating_mode 0 "off" 1 "cool" 2 "heat" 3 "auto" 4 "fan only" ;
VAL_ 130809 fan_mode 0 "auto" 1 "on" ;
VAL_ 130809 schedule_mode 0 "disabled" 1 "enabled" ;

BO_ 130808 THERMOSTAT_COMMAND_2: 2 RVCController
 SG_ instance : 0|8@1+ (1,0) [0|0] "" RVCController
 SG_ current_schedule_instance : 8|8@1+ (1,0) [0|0] "" RVCController

// Messages 1FEF7 to 1FEF4 have empty definitions in YAML, leaving DBC as is.
BO_ 130807 THERMOSTAT_SCHEDULE_STATUS_1: 1 RVCController
// ...existing code...
BO_ 130804 THERMOSTAT_SCHEDULE_COMMAND_2: 1 RVCController
// ...existing code...
BO_ 130972 THERMOSTAT_AMBIENT_STATUS: 3 RVCController
 SG_ instance : 0|8@1+ (1,0) [0|0] "" RVCController
 SG_ ambient_temp : 8|16@1+ (0.1,0) [0|0] "Deg C" RVCController // Assuming scaling

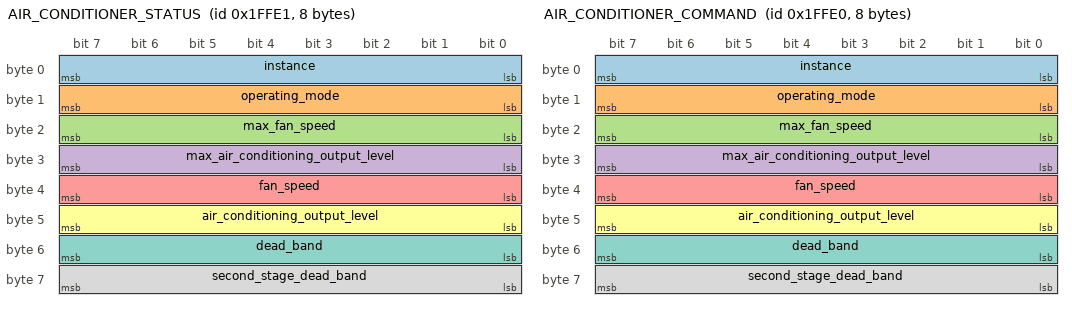
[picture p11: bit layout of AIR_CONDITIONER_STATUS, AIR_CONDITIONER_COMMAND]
BO_ 131041 AIR_CONDITIONER_STATUS: 8 RVCController
 SG_ instance : 0|8@1+ (1,0) [0|0] "" RVCController
 SG_ operating_mode : 8|8@1+ (1,0) [0|0] "" RVCController
 SG_ max_fan_speed : 16|8@1+ (0.5,0) [0|0] "Pct" RVCController // Assuming scaling
 SG_ max_air_conditioning_output_level : 24|8@1+ (0.5,0) [0|0] "Pct" RVCController // Assuming scaling
 SG_ fan_speed : 32|8@1+ (0.5,0) [0|0] "Pct" RVCController // Assuming scaling
 SG_ air_conditioning_output_level : 40|8@1+ (0.5,0) [0|0] "Pct" RVCController // Assuming scaling
 SG_ dead_band : 48|8@1+ (0.1,0) [0|0] "" RVCController // Assuming scaling, removed unit uint8
 SG_ second_stage_dead_band : 56|8@1+ (0.1,0) [0|0] "" RVCController // Assuming scaling, removed unit uint8
VAL_ 131041 operating_mode 0 "automatic" 1 "manual" ;

// Add missing alias from YAML: 1FFE0 AIR_CONDITIONER_COMMAND (alias of 1FFE1)
BO_ 131040 AIR_CONDITIONER_COMMAND: 8 RVCController
 SG_ instance : 0|8@1+ (1,0) [0|0] "" RVCController
 SG_ operating_mode : 8|8@1+ (1,0) [0|0] "" RVCController
 SG_ max_fan_speed : 16|8@1+ (0.5,0) [0|0] "Pct" RVCController // Assuming scaling
 SG_ max_air_conditioning_output_level : 24|8@1+ (0.5,0) [0|0] "Pct" RVCController // Assuming scaling
 SG_ fan_speed : 32|8@1+ (0.5,0) [0|0] "Pct" RVCController // Assuming scaling
 SG_ air_conditioning_output_level : 40|8@1+ (0.5,0) [0|0] "Pct" RVCController // Assuming scaling
 SG_ dead_band : 48|8@1+ (0.1,0) [0|0] "" RVCController // Assuming scaling
 SG_ second_stage_dead_band : 56|8@1+ (0.1,0) [0|0] "" RVCController // Assuming scaling
VAL_ 131040 operating_mode 0 "automatic" 1 "manual" ;

BO_ 130971 HEAT_PUMP_STATUS: 1 RVCController
// YAML empty, leaving as is

// Add missing alias from YAML: 1FF9A HEAT_PUMP_COMMAND (alias of 1FF9B)
BO_ 130970 HEAT_PUMP_COMMAND: 1 RVCController
// YAML empty, leaving as is

BO_ 131039 GENERATOR_AC_STATUS_1: 1 RVCController
 SG_ instance : 0|4@1+ (1,0) [0|0] "" RVCController
 SG_ line : 4|4@1+ (1,0) [0|0] "" RVCController

BO_ 131038 GENERATOR_AC_STATUS_2: 1 RVCController
 SG_ instance : 0|4@1+ (1,0) [0|0] "" RVCController
 SG_ line : 4|4@1+ (1,0) [0|0] "" RVCController

BO_ 131037 GENERATOR_AC_STATUS_3: 1 RVCController
 SG_ instance : 0|4@1+ (1,0) [0|0] "" RVCController
 SG_ line : 4|4@1+ (1,0) [0|0] "" RVCController

BO_ 130964 GENERATOR_AC_STATUS_4: 1 RVCController
 SG_ instance : 0|4@1+ (1,0) [0|0] "" RVCController
 SG_ line : 4|4@1+ (1,0) [0|0] "" RVCController

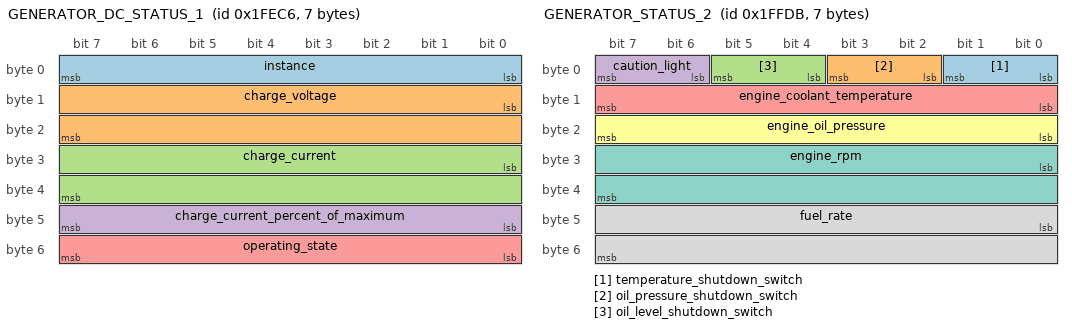
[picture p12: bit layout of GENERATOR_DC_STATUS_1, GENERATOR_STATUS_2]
BO_ 130758 GENERATOR_DC_STATUS_1: 7 RVCController
 SG_ instance : 0|8@1+ (1,0) [0|0] "" RVCController
 SG_ charge_voltage : 8|16@1+ (0.001,0) [0|0] "v" RVCController // Assuming scaling
 SG_ charge_current : 24|16@1+ (0.1,0) [0|0] "a" RVCController // Assuming scaling
 SG_ charge_current_percent_of_maximum : 40|8@1+ (0.5,0) [0|0] "pct" RVCController // Assuming scaling
 SG_ operating_state : 48|8@1+ (1,0) [0|0] "" RVCController
 // Missing VAL_ for operating_state in DBC, but present in CHARGER_STATUS (1FFC7). Adding it here.
 VAL_ 130758 operating_state 0 "undefined" 1 "do not charge" 2 "bulk" 3 "absorption" 4 "overcharge" 5 "equalize" 6 "float" 7 "constant voltage/current" ;

// Messages 1FEC5 to 1FEC0 have empty definitions in YAML, leaving DBC as is or missing.
BO_ 130757 GENERATOR_DC_CONFIGURATION_STATUS: 1 RVCController
// ...existing code...
BO_ 130752 GENERATOR_DC_EQUALIZATION_CONFIGURATION_COMMAND: 1 RVCController
// ...existing code...
BO_ 131036 GENERATOR_STATUS_1: 8 RVCController
 SG_ status : 0|8@1+ (1,0) [0|0] "" RVCController
 SG_ engine_run_time : 8|32@1+ (1,0) [0|0] "" RVCController
 SG_ engine_load : 40|8@1+ (0.5,0) [0|0] "pct" RVCController // Assuming scaling
 SG_ start_battery_voltage : 48|16@1+ (0.001,0) [0|0] "v" RVCController // Assuming scaling
VAL_ 131036 status 0 "stopped" 1 "preheat" 2 "cranking" 3 "running" 4 "priming" 5 "fault" 6 "engine run only" 7 "test mode" 8 "voltage adjust mode" 9 "fault bypass mode" 10 "configuration mode" ; // Corrected value 10

BO_ 131035 GENERATOR_STATUS_2: 7 RVCController
 SG_ temperature_shutdown_switch : 0|2@1+ (1,0) [0|0] "" RVCController
 SG_ oil_pressure_shutdown_switch : 2|2@1+ (1,0) [0|0] "" RVCController
 SG_ oil_level_shutdown_switch : 4|2@1+ (1,0) [0|0] "" RVCController
 SG_ caution_light : 6|2@1+ (1,0) [0|0] "" RVCController
 SG_ engine_coolant_temperature : 8|8@1+ (1,-40) [0|0] "deg c" RVCController // Assuming scaling
 SG_ engine_oil_pressure : 16|8@1+ (1,0) [0|0] "kPa" RVCController
 SG_ engine_rpm : 24|16@1+ (1,0) [0|0] "RPM" RVCController
 SG_ fuel_rate : 40|16@1+ (0.01,0) [0|0] "lph" RVCController // Assuming scaling
VAL_ 131035 temperature_shutdown_switch 0 "temperature shutdown not active" 1 "temperature shutdown active" ;
VAL_ 131035 oil_pressure_shutdown_switch 0 "oil pressure shutdown not active" 1 "oil pressure shutdown active" ;
VAL_ 131035 oil_level_shutdown_switch 0 "oil level switch not active" 1 "low oil level detected" ;
VAL_ 131035 caution_light 0 "caution light off" 1 "caution light on" ;

BO_ 131034 GENERATOR_COMMAND: 1 RVCController
 SG_ command : 0|8@1+ (1,0) [0|0] "" RVCController
VAL_ 131034 command 0 "stop" 1 "start" 2 "manual prime" 3 "manual preheat" ;

BO_ 131033 GENERATOR_START_CONFIG_STATUS: 1 RVCController
// YAML empty, leaving as is
BO_ 131032 GENERATOR_START_CONFIG_COMMAND: 1 RVCController
// YAML empty, leaving as is

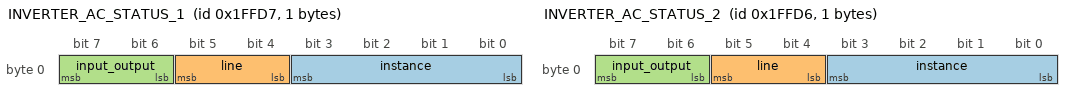
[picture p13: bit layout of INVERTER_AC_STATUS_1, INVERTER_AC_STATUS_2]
BO_ 131031 INVERTER_AC_STATUS_1: 1 RVCController
 SG_ instance : 0|4@1+ (1,0) [0|0] "" RVCController
 SG_ line : 4|2@1+ (1,0) [0|0] "" RVCController
 SG_ input_output : 6|2@1+ (1,0) [0|0] "" RVCController
VAL_ 131031 line 0 "1" 1 "2" ;
VAL_ 131031 input_output 0 "input" 1 "output" ;

BO_ 131030 INVERTER_AC_STATUS_2: 1 RVCController
 SG_ instance : 0|4@1+ (1,0) [0|0] "" RVCController
 SG_ line : 4|2@1+ (1,0) [0|0] "" RVCController
 SG_ input_output : 6|2@1+ (1,0) [0|0] "" RVCController
VAL_ 131030 line 0 "1" 1 "2" ;
VAL_ 131030 input_output 0 "input" 1 "output" ;

BO_ 131029 INVERTER_AC_STATUS_3: 1 RVCController
 SG_ instance : 0|4@1+ (1,0) [0|0] "" RVCController
 SG_ line : 4|2@1+ (1,0) [0|0] "" RVCController
 SG_ input_output : 6|2@1+ (1,0) [0|0] "" RVCController
VAL_ 131029 line 0 "1" 1 "2" ;
VAL_ 131029 input_output 0 "input" 1 "output" ;

BO_ 130959 INVERTER_AC_STATUS_4: 1 RVCController
 SG_ instance : 0|4@1+ (1,0) [0|0] "" RVCController
 SG_ line : 4|2@1+ (1,0) [0|0] "" RVCController
 SG_ input_output : 6|2@1+ (1,0) [0|0] "" RVCController
VAL_ 130959 line 0 "1" 1 "2" ;
VAL_ 130959 input_output 0 "input" 1 "output" ;

// Add missing aliases from YAML: 1FF8E to 1FF8B (INVERTER_ACFAULT) - Assuming empty definitions
BO_ 130958 INVERTER_ACFAULT_CONFIGURATION_STATUS_1: 1 RVCController
BO_ 130957 INVERTER_ACFAULT_CONFIGURATION_STATUS_2: 1 RVCController
BO_ 130956 INVERTER_ACFAULT_CONFIGURATION_COMMAND_1: 1 RVCController
BO_ 130955 INVERTER_ACFAULT_CONFIGURATION_COMMAND_2: 1 RVCController

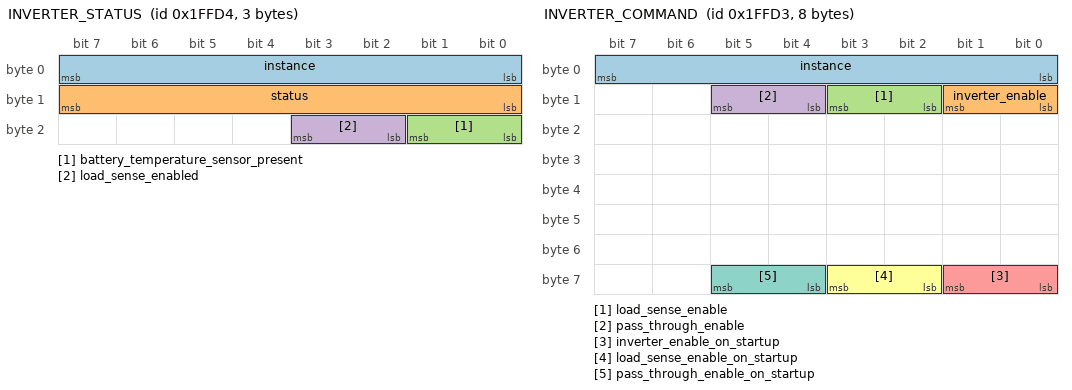
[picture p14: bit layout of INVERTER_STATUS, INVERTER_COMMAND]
BO_ 131028 INVERTER_STATUS: 3 RVCController
 SG_ instance : 0|8@1+ (1,0) [0|0] "" RVCController
 SG_ status : 8|8@1+ (1,0) [0|0] "" RVCController
 SG_ battery_temperature_sensor_present : 16|2@1+ (1,0) [0|0] "" RVCController
 SG_ load_sense_enabled : 18|2@1+ (1,0) [0|0] "" RVCController // Corrected bit position from YAML comment
VAL_ 131028 status 0 "disabled" 1 "invert" 2 "ac passthru" 3 "aps only" 4 "load sense" 5 "waiting to invert" ;
VAL_ 131028 battery_temperature_sensor_present 0 "no sensor in use" 1 "sensor present and active" ;
VAL_ 131028 load_sense_enabled 0 "load sense disabled" 1 "load sense enabled" ;

BO_ 131027 INVERTER_COMMAND: 8 RVCController
 SG_ instance : 0|8@1+ (1,0) [0|0] "" RVCController
 SG_ inverter_enable : 8|2@1+ (1,0) [0|0] "" RVCController
 SG_ load_sense_enable : 10|2@1+ (1,0) [0|0] "" RVCController
 SG_ pass_through_enable : 12|2@1+ (1,0) [0|0] "" RVCController
 // Reserved bits 14-55
 SG_ inverter_enable_on_startup : 56|2@1+ (1,0) [0|0] "" RVCController
 SG_ load_sense_enable_on_startup : 58|2@1+ (1,0) [0|0] "" RVCController
 SG_ pass_through_enable_on_startup : 60|2@1+ (1,0) [0|0] "" RVCController // Corrected bit position
 // Reserved bits 62-63
VAL_ 131027 inverter_enable 0 "disable" 1 "enable" ;
VAL_ 131027 load_sense_enable 0 "disable" 1 "enable" ;
VAL_ 131027 pass_through_enable 0 "disable" 1 "enable" ;
VAL_ 131027 inverter_enable_on_startup 0 "disable" 1 "enable" ;
VAL_ 131027 load_sense_enable_on_startup 0 "disable" 1 "enable" ;
VAL_ 131027 pass_through_enable_on_startup 0 "disable" 1 "enable" ; // Removed duplicate VAL entry

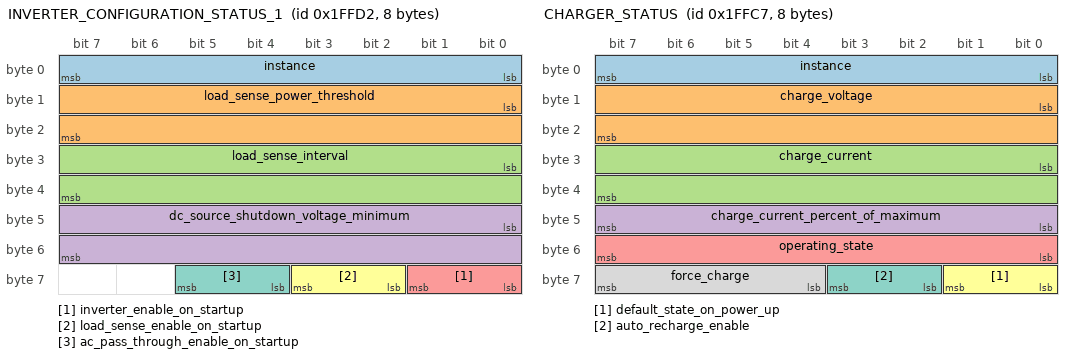
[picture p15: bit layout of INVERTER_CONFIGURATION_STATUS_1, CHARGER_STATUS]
BO_ 131026 INVERTER_CONFIGURATION_STATUS_1: 8 RVCController
 SG_ instance : 0|8@1+ (1,0) [0|0] "" RVCController
 SG_ load_sense_power_threshold : 8|16@1+ (1,0) [0|0] "w" RVCController
 SG_ load_sense_interval : 24|16@1+ (1,0) [0|0] "sec" RVCController
 SG_ dc_source_shutdown_voltage_minimum : 40|16@1+ (0.001,0) [0|0] "v" RVCController // Assuming scaling
 SG_ inverter_enable_on_startup : 56|2@1+ (1,0) [0|0] "" RVCController
 SG_ load_sense_enable_on_startup : 58|2@1+ (1,0) [0|0] "" RVCController
 SG_ ac_pass_through_enable_on_startup : 60|2@1+ (1,0) [0|0] "" RVCController
 // Reserved bits 62-63
VAL_ 131026 inverter_enable_on_startup 0 "disabled" 1 "enabled" ;
VAL_ 131026 load_sense_enable_on_startup 0 "disabled" 1 "enabled" ;
VAL_ 131026 ac_pass_through_enable_on_startup 0 "disabled" 1 "enabled" ;

BO_ 131025 INVERTER_CONFIGURATION_STATUS_2: 7 RVCController
 SG_ instance : 0|8@1+ (1,0) [0|0] "" RVCController
 SG_ dc_source_shutdown_voltage_maximum : 8|16@1+ (0.001,0) [0|0] "v" RVCController // Assuming scaling
 SG_ dc_source_warning_voltage_minimum : 24|16@1+ (0.001,0) [0|0] "v" RVCController // Assuming scaling
 SG_ dc_source_warning_voltage_maximum : 40|16@1+ (0.001,0) [0|0] "v" RVCController // Corrected name based on YAML (was shutdown max)

BO_ 130766 INVERTER_CONFIGURATION_STATUS_3: 4 RVCController
 SG_ instance : 0|8@1+ (1,0) [0|0] "" RVCController
 SG_ dc_source_shutdown_delay : 8|16@1+ (1,0) [0|0] "sec" RVCController
 SG_ stack_mode : 24|8@1+ (1,0) [0|0] "" RVCController
VAL_ 130766 stack_mode 0 "stand-alone" 1 "master" 2 "slave" 3 "line 2 master" ;

BO_ 131024 INVERTER_CONFIGURATION_COMMAND_1: 7 RVCController
 SG_ instance : 0|8@1+ (1,0) [0|0] "" RVCController
 SG_ load_sense_power_threshold : 8|16@1+ (1,0) [0|0] "w" RVCController
 SG_ load_sense_interval : 24|16@1+ (1,0) [0|0] "sec" RVCController
 SG_ dc_source_shutdown_voltage_minimum : 40|16@1+ (0.001,0) [0|0] "v" RVCController // Assuming scaling

BO_ 131023 INVERTER_CONFIGURATION_COMMAND_2: 7 RVCController
 SG_ instance : 0|8@1+ (1,0) [0|0] "" RVCController
 SG_ dc_source_shutdown_voltage_maximum : 8|16@1+ (0.001,0) [0|0] "v" RVCController // Assuming scaling
 SG_ dc_source_warning_voltage_minimum : 24|16@1+ (0.001,0) [0|0] "v" RVCController // Assuming scaling
 SG_ dc_source_warning_voltage_maximum : 40|16@1+ (0.001,0) [0|0] "v" RVCController // Corrected name based on YAML (was shutdown max)

BO_ 130765 INVERTER_CONFIGURATION_COMMAND_3: 4 RVCController
 SG_ instance : 0|8@1+ (1,0) [0|0] "" RVCController
 SG_ dc_source_shutdown_delay : 8|16@1+ (1,0) [0|0] "sec" RVCController
 SG_ stack_mode : 24|8@1+ (1,0) [0|0] "" RVCController
VAL_ 130765 stack_mode 0 "stand-alone" 1 "master" 2 "slave" 3 "line 2 master" ;

// Messages 1FFCE to 1FFCB have empty definitions in YAML, leaving DBC as is.
BO_ 131022 INVERTER_STATISTIC_STATUS: 1 RVCController
// ...existing code...
BO_ 131019 INVERTER_OPE_STATUS: 1 RVCController
// ...existing code...
BO_ 130792 INVERTER_DC_STATUS: 5 RVCController
 SG_ instance : 0|8@1+ (1,0) [0|0] "" RVCController
 SG_ dc_voltage : 8|16@1+ (0.001,0) [0|0] "v" RVCController // Assuming scaling
 SG_ dc_amperage : 24|16@1+ (0.1,0) [0|0] "a" RVCController // Assuming scaling

BO_ 130749 INVERTER_TEMPERATURE_STATUS: 5 RVCController
 SG_ instance : 0|8@1+ (1,0) [0|0] "" RVCController
 SG_ fet_temperature : 8|16@1+ (0.1,-40) [0|0] "deg c" RVCController // Assuming scaling
 SG_ transformer_temperature : 24|16@1+ (0.1,-40) [0|0] "deg c" RVCController // Assuming scaling

BO_ 131018 CHARGER_AC_STATUS_1: 1 RVCController
 SG_ instance : 0|4@1+ (1,0) [0|0] "" RVCController
 SG_ line : 4|2@1+ (1,0) [0|0] "" RVCController
 SG_ input_output : 6|2@1+ (1,0) [0|0] "" RVCController
VAL_ 131018 line 0 "1" 1 "2" ;
VAL_ 131018 input_output 0 "input" 1 "output" ;

BO_ 131017 CHARGER_AC_STATUS_2: 1 RVCController
 SG_ instance : 0|4@1+ (1,0) [0|0] "" RVCController
 SG_ line : 4|2@1+ (1,0) [0|0] "" RVCController
 SG_ input_output : 6|2@1+ (1,0) [0|0] "" RVCController
VAL_ 131017 line 0 "1" 1 "2" ;
VAL_ 131017 input_output 0 "input" 1 "output" ;

BO_ 131016 CHARGER_AC_STATUS_3: 1 RVCController
 SG_ instance : 0|4@1+ (1,0) [0|0] "" RVCController
 SG_ line : 4|2@1+ (1,0) [0|0] "" RVCController
 SG_ input_output : 6|2@1+ (1,0) [0|0] "" RVCController
VAL_ 131016 line 0 "1" 1 "2" ;
VAL_ 131016 input_output 0 "input" 1 "output" ;

BO_ 130954 CHARGER_AC_STATUS_4: 1 RVCController
 SG_ instance : 0|4@1+ (1,0) [0|0] "" RVCController
 SG_ line : 4|2@1+ (1,0) [0|0] "" RVCController
 SG_ input_output : 6|2@1+ (1,0) [0|0] "" RVCController
VAL_ 130954 line 0 "1" 1 "2" ;
VAL_ 130954 input_output 0 "input" 1 "output" ;

// Add missing aliases from YAML: 1FF89 to 1FF86 (CHARGER_ACFAULT) - Assuming empty definitions
BO_ 130953 CHARGER_ACFAULT_CONFIGURATION_STATUS_1: 1 RVCController
BO_ 130952 CHARGER_ACFAULT_CONFIGURATION_STATUS_2: 1 RVCController
BO_ 130951 CHARGER_ACFAULT_CONFIGURATION_COMMAND_1: 1 RVCController
BO_ 130950 CHARGER_ACFAULT_CONFIGURATION_COMMAND_2: 1 RVCController

BO_ 131015 CHARGER_STATUS: 8 RVCController
 SG_ instance : 0|8@1+ (1,0) [0|0] "" RVCController
 SG_ charge_voltage : 8|16@1+ (0.001,0) [0|0] "v" RVCController // Assuming scaling
 SG_ charge_current : 24|16@1+ (0.1,0) [0|0] "a" RVCController // Assuming scaling
 SG_ charge_current_percent_of_maximum : 40|8@1+ (0.5,0) [0|0] "pct" RVCController // Assuming scaling
 SG_ operating_state : 48|8@1+ (1,0) [0|0] "" RVCController
 SG_ default_state_on_power_up : 56|2@1+ (1,0) [0|0] "" RVCController
 SG_ auto_recharge_enable : 58|2@1+ (1,0) [0|0] "" RVCController
 SG_ force_charge : 60|4@1+ (1,0) [0|0] "" RVCController
VAL_ 131015 operating_state 0 "undefined" 1 "do not charge" 2 "bulk" 3 "absorption" 4 "overcharge" 5 "equalize" 6 "float" 7 "constant voltage/current" ;
VAL_ 131015 default_state_on_power_up 0 "disabled" 1 "enabled" ;
VAL_ 131015 auto_recharge_enable 0 "disabled" 1 "enabled" ;
VAL_ 131015 force_charge 0 "charging not forced" 1 "force charge to bulk" 2 "force charge to float" ;

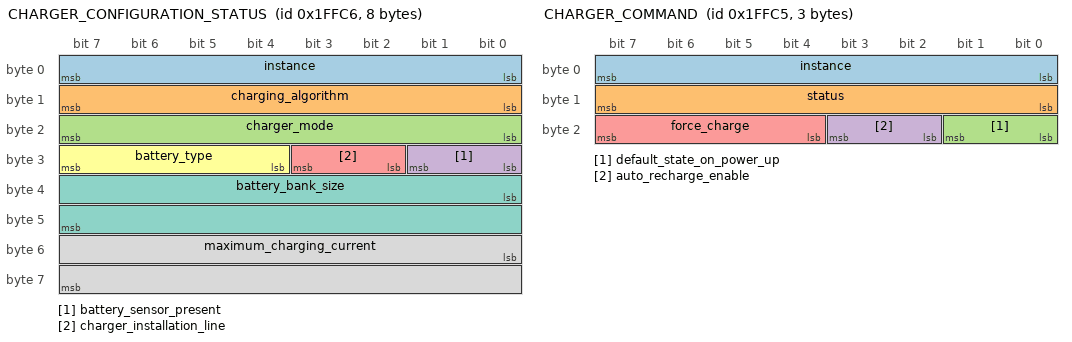
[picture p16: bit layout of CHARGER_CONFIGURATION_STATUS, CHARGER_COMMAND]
BO_ 131014 CHARGER_CONFIGURATION_STATUS: 8 RVCController
 SG_ instance : 0|8@1+ (1,0) [0|0] "" RVCController
 SG_ charging_algorithm : 8|8@1+ (1,0) [0|0] "" RVCController
 SG_ charger_mode : 16|8@1+ (1,0) [0|0] "" RVCController
 SG_ battery_sensor_present : 24|2@1+ (1,0) [0|0] "" RVCController
 SG_ charger_installation_line : 26|2@1+ (1,0) [0|0] "" RVCController
 SG_ battery_type : 28|4@1+ (1,0) [0|0] "" RVCController
 SG_ battery_bank_size : 32|16@1+ (1,0) [0|0] "ah" RVCController
 SG_ maximum_charging_current : 48|16@1+ (0.1,0) [0|0] "a" RVCController // Corrected length, assuming scaling
VAL_ 131014 charging_algorithm 0 "constant voltage" 1 "constant current" 2 "3-stage" 3 "2-stage" 4 "trickle" 249 "custom 2" 250 "custom 1" ;
VAL_ 131014 charger_mode 0 "stand-alone" 1 "primary" 2 "secondary" 3 "linked to dc source" ;
VAL_ 131014 battery_sensor_present 0 "no sensor in use" 1 "sensor present and active" ;
VAL_ 131014 charger_installation_line 0 "1" 1 "2" ;
VAL_ 131014 battery_type 0 "flooded" 1 "gel" 2 "agm" 3 "lithium iron phosphate" ;

BO_ 131013 CHARGER_COMMAND: 3 RVCController
 SG_ instance : 0|8@1+ (1,0) [0|0] "" RVCController
 SG_ status : 8|8@1+ (1,0) [0|0] "" RVCController
 SG_ default_state_on_power_up : 16|2@1+ (1,0) [0|0] "" RVCController
 SG_ auto_recharge_enable : 18|2@1+ (1,0) [0|0] "" RVCController
 SG_ force_charge : 20|4@1+ (1,0) [0|0] "" RVCController
VAL_ 131013 status 0 "disable" 1 "enable charger" 2 "start equalization" ;
VAL_ 131013 default_state_on_power_up 0 "disabled" 1 "enabled" ;
VAL_ 131013 auto_recharge_enable 0 "disabled" 1 "enabled" ;
VAL_ 131013 force_charge 0 "cancel forcing" 1 "force charge to bulk" 2 "force charge to float" ;

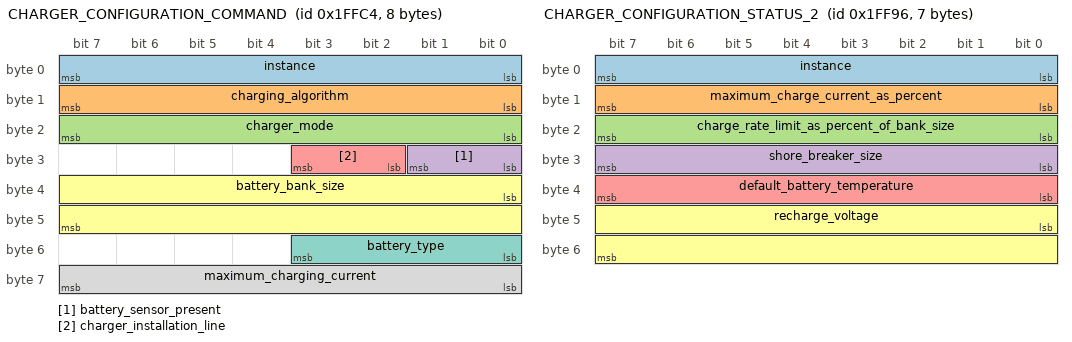
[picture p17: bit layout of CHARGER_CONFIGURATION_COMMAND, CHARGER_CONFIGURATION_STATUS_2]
BO_ 131012 CHARGER_CONFIGURATION_COMMAND: 8 RVCController
 SG_ instance : 0|8@1+ (1,0) [0|0] "" RVCController
 SG_ charging_algorithm : 8|8@1+ (1,0) [0|0] "" RVCController
 SG_ charger_mode : 16|8@1+ (1,0) [0|0] "" RVCController
 SG_ battery_sensor_present : 24|2@1+ (1,0) [0|0] "" RVCController
 SG_ charger_installation_line : 26|2@1+ (1,0) [0|0] "" RVCController
 SG_ battery_bank_size : 32|16@1+ (1,0) [0|0] "ah" RVCController
 SG_ battery_type : 48|4@1+ (1,0) [0|0] "" RVCController // Corrected start bit
 SG_ maximum_charging_current : 56|8@1+ (0.1,0) [0|0] "a" RVCController // Assuming scaling
VAL_ 131012 charging_algorithm 0 "constant voltage" 1 "constant current" 2 "3-stage" 3 "2-stage" 4 "trickle" 249 "custom 2" 250 "custom 1" ;
VAL_ 131012 charger_mode 0 "stand-alone" 1 "primary" 2 "secondary" 3 "linked to dc source" ;
VAL_ 131012 battery_sensor_present 0 "no sensor in use" 1 "sensor present and active" ;
VAL_ 131012 charger_installation_line 0 "1" 1 "2" ;
VAL_ 131012 battery_type 0 "flooded" 1 "gel" 2 "agm" 3 "lithium iron phosphate" ;

BO_ 130966 CHARGER_CONFIGURATION_STATUS_2: 7 RVCController
 SG_ instance : 0|8@1+ (1,0) [0|0] "" RVCController
 SG_ maximum_charge_current_as_percent : 8|8@1+ (0.5,0) [0|0] "pct" RVCController // Assuming scaling
 SG_ charge_rate_limit_as_percent_of_bank_size : 16|8@1+ (0.5,0) [0|0] "pct" RVCController // Assuming scaling
 SG_ shore_breaker_size : 24|8@1+ (1,0) [0|0] "a" RVCController
 SG_ default_battery_temperature : 32|8@1+ (1,-40) [0|0] "deg c" RVCController // Assuming scaling
 SG_ recharge_voltage : 40|16@1+ (0.001,0) [0|0] "v" RVCController // Assuming scaling

// Add missing alias from YAML: 1FF95 CHARGER_CONFIGURATION_COMMAND_2 (alias of 1FF96)
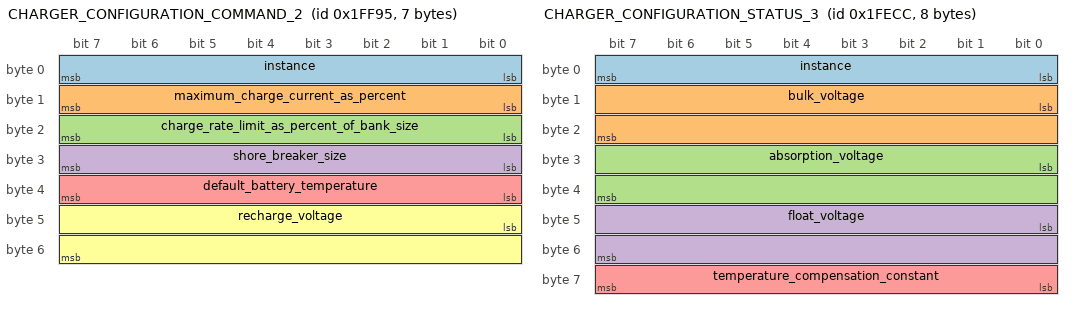
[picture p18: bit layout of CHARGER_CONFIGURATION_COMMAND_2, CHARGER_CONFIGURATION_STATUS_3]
BO_ 130965 CHARGER_CONFIGURATION_COMMAND_2: 7 RVCController
 SG_ instance : 0|8@1+ (1,0) [0|0] "" RVCController
 SG_ maximum_charge_current_as_percent : 8|8@1+ (0.5,0) [0|0] "pct" RVCController // Assuming scaling
 SG_ charge_rate_limit_as_percent_of_bank_size : 16|8@1+ (0.5,0) [0|0] "pct" RVCController // Assuming scaling
 SG_ shore_breaker_size : 24|8@1+ (1,0) [0|0] "a" RVCController
 SG_ default_battery_temperature : 32|8@1+ (1,-40) [0|0] "deg c" RVCController // Assuming scaling
 SG_ recharge_voltage : 40|16@1+ (0.001,0) [0|0] "v" RVCController // Assuming scaling

BO_ 130764 CHARGER_CONFIGURATION_STATUS_3: 8 RVCController
 SG_ instance : 0|8@1+ (1,0) [0|0] "" RVCController
 SG_ bulk_voltage : 8|16@1+ (0.001,0) [0|0] "v" RVCController // Assuming scaling
 SG_ absorption_voltage : 24|16@1+ (0.001,0) [0|0] "v" RVCController // Assuming scaling
 SG_ float_voltage : 40|16@1+ (0.001,0) [0|0] "v" RVCController // Assuming scaling
 SG_ temperature_compensation_constant : 56|8@1+ (0.001,0) [0|0] "mV/K" RVCController // Assuming scaling

// Add missing alias from YAML: 1FECB CHARGER_CONFIGURATION_COMMAND_3 (alias of 1FECC)
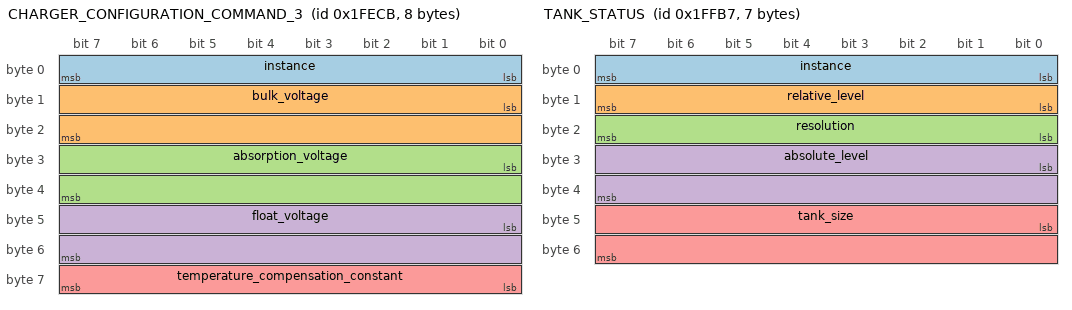
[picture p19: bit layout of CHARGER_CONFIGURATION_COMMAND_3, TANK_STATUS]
BO_ 130763 CHARGER_CONFIGURATION_COMMAND_3: 8 RVCController
 SG_ instance : 0|8@1+ (1,0) [0|0] "" RVCController
 SG_ bulk_voltage : 8|16@1+ (0.001,0) [0|0] "v" RVCController // Assuming scaling
 SG_ absorption_voltage : 24|16@1+ (0.001,0) [0|0] "v" RVCController // Assuming scaling
 SG_ float_voltage : 40|16@1+ (0.001,0) [0|0] "v" RVCController // Assuming scaling
 SG_ temperature_compensation_constant : 56|8@1+ (0.001,0) [0|0] "mV/K" RVCController // Assuming scaling

BO_ 130751 CHARGER_CONFIGURATION_STATUS_4: 7 RVCController
 SG_ instance : 0|8@1+ (1,0) [0|0] "" RVCController
 SG_ bulk_time : 8|16@1+ (1,0) [0|0] "min" RVCController
 SG_ absorption_time : 24|16@1+ (1,0) [0|0] "min" RVCController
 SG_ float_time : 40|16@1+ (1,0) [0|0] "min" RVCController

// Add missing alias from YAML: 1FEBE CHARGER_CONFIGURATION_COMMAND_4 (alias of 1FEBF)
BO_ 130750 CHARGER_CONFIGURATION_COMMAND_4: 7 RVCController
 SG_ instance : 0|8@1+ (1,0) [0|0] "" RVCController
 SG_ bulk_time : 8|16@1+ (1,0) [0|0] "min" RVCController
 SG_ absorption_time : 24|16@1+ (1,0) [0|0] "min" RVCController
 SG_ float_time : 40|16@1+ (1,0) [0|0] "min" RVCController

BO_ 130969 CHARGER_EQUALIZATION_STATUS: 4 RVCController
 SG_ instance : 0|8@1+ (1,0) [0|0] "" RVCController
 SG_ time_remaining : 8|16@1+ (1,0) [0|0] "min" RVCController
 SG_ pre_charging_status : 24|2@1+ (1,0) [0|0] "" RVCController
VAL_ 130969 pre_charging_status 0 "pre-charging not in process" 1 "charging batteries to prepare for equalization" ;

BO_ 130968 CHARGER_EQUALIZATION_CONFIGURATION_STATUS: 5 RVCController
 SG_ instance : 0|8@1+ (1,0) [0|0] "" RVCController
 SG_ equalization_voltage : 8|16@1+ (0.001,0) [0|0] "v" RVCController // Assuming scaling
 SG_ equalization_time : 24|16@1+ (1,0) [0|0] "min" RVCController

// Add missing alias from YAML: 1FF97 CHARGER_EQUALIZATION_CONFIGURATION_COMMAND (alias of 1FF98)
BO_ 130967 CHARGER_EQUALIZATION_CONFIGURATION_COMMAND: 5 RVCController
 SG_ instance : 0|8@1+ (1,0) [0|0] "" RVCController
 SG_ equalization_voltage : 8|16@1+ (0.001,0) [0|0] "v" RVCController // Assuming scaling
 SG_ equalization_time : 24|16@1+ (1,0) [0|0] "min" RVCController

BO_ 130747 GENERIC_AC_STATUS_1: 1 RVCController
 SG_ instance : 0|4@1+ (1,0) [0|0] "" RVCController
 SG_ line : 4|4@1+ (1,0) [0|0] "" RVCController // Changed length from 8 to 4 based on pattern

BO_ 130746 GENERIC_AC_STATUS_2: 1 RVCController
 SG_ instance : 0|4@1+ (1,0) [0|0] "" RVCController
 SG_ line : 4|4@1+ (1,0) [0|0] "" RVCController // Changed length from 8 to 4 based on pattern

BO_ 130745 GENERIC_AC_STATUS_3: 1 RVCController
 SG_ instance : 0|4@1+ (1,0) [0|0] "" RVCController
 SG_ line : 4|4@1+ (1,0) [0|0] "" RVCController // Changed length from 8 to 4 based on pattern

BO_ 130744 GENERIC_AC_STATUS_4: 1 RVCController
 SG_ instance : 0|4@1+ (1,0) [0|0] "" RVCController
 SG_ line : 4|4@1+ (1,0) [0|0] "" RVCController // Changed length from 8 to 4 based on pattern

// Add missing aliases from YAML: 1FEB7 to 1FEB4 (GENERIC_ACFAULT) - Assuming empty definitions
BO_ 130743 GENERIC_ACFAULT_CONFIGURATION_STATUS_1: 1 RVCController
BO_ 130742 GENERIC_ACFAULT_CONFIGURATION_STATUS_2: 1 RVCController
BO_ 130741 GENERIC_ACFAULT_CONFIGURATION_COMMAND_1: 1 RVCController
BO_ 130740 GENERIC_ACFAULT_CONFIGURATION_COMMAND_2: 1 RVCController

// Messages 1FFBF to 1FFBA have incomplete definitions in YAML, leaving DBC as is.
BO_ 131007 AC_LOAD_STATUS: 8 RVCController
// ...existing code...
BO_ 130781 AC_LOAD_STATUS_2: 4 RVCController
// ...existing code...
BO_ 131006 AC_LOAD_COMMAND: 6 RVCController
// ...existing code...
BO_ 131005 DC_LOAD_STATUS: 8 RVCController // Corrected ID (was 130780)
// ...existing code...
BO_ 130780 DC_LOAD_STATUS_2: 4 RVCController
// ...existing code...
BO_ 131004 DC_LOAD_COMMAND: 6 RVCController
// ...existing code...
BO_ 131003 DC_DIMMER_STATUS_1: 6 RVCController
// ...existing code...
BO_ 131002 DC_DIMMER_STATUS_2: 6 RVCController
// ...existing code...
BO_ 130778 DC_DIMMER_STATUS_3: 8 RVCController
// ...existing code...
BO_ 130779 DC_DIMMER_COMMAND_2: 6 RVCController
// ...existing code...

// Remaining messages have empty or incomplete definitions in YAML, leaving DBC as is.
BO_ 131000 DIGITAL_INPUT_STATUS: 1 RVCController
// ...existing code...
BO_ 130775 GENERIC_INDICATOR_STATUS: 7 RVCController
// ...existing code...
BO_ 130777 GENERIC_INDICATOR_COMMAND: 7 RVCController
// ...existing code...
BO_ 130784 DC_MOTOR_CONTROL_STATUS: 1 RVCController
// ...existing code...
BO_ 130785 DC_MOTOR_CONTROL_COMMAND: 1 RVCController
// ...existing code...
BO_ 130999 TANK_STATUS: 7 RVCController
 SG_ instance : 0|8@1+ (1,0) [0|0] "" RVCController // Corrected length
 SG_ relative_level : 8|8@1+ (0.5,0) [0|0] "" RVCController // Corrected length, assuming scaling
 SG_ resolution : 16|8@1+ (1,0) [0|0] "" RVCController // Corrected length
 SG_ absolute_level : 24|16@1+ (0.1,0) [0|0] "Liter" RVCController // Assuming scaling
 SG_ tank_size : 40|16@1+ (1,0) [0|0] "Liter" RVCController
VAL_ 130999 instance 0 "fresh water" 1 "black waste" 2 "gray waste" 3 "lpg" 16 "second fresh water" 17 "second black waste" 18 "second gray waste" 19 "second lpg" ;

// ... rest of the file ...
